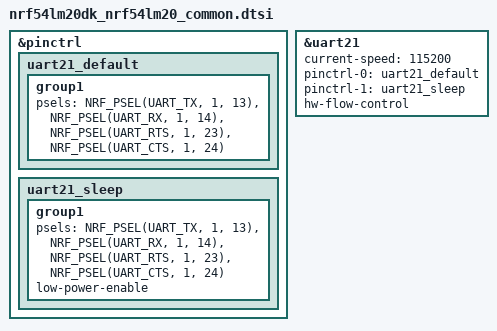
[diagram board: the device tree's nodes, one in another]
/* SPDX-License-Identifier: Apache-2.0 */

/* Test requires loopbacks:
 * P1.13 - P1.14
 * P1.23 - P1.24
 */

&pinctrl {
	uart21_default: uart21_default {
		group1 {
			psels = <NRF_PSEL(UART_TX, 1, 13)>,
				<NRF_PSEL(UART_RX, 1, 14)>,
				<NRF_PSEL(UART_RTS, 1, 23)>,
				<NRF_PSEL(UART_CTS, 1, 24)>;
		};
	};

	uart21_sleep: uart21_sleep {
		group1 {
			psels = <NRF_PSEL(UART_TX, 1, 13)>,
				<NRF_PSEL(UART_RX, 1, 14)>,
				<NRF_PSEL(UART_RTS, 1, 23)>,
				<NRF_PSEL(UART_CTS, 1, 24)>;
			low-power-enable;
		};
	};
};

dut: &uart21 {
	status = "okay";
	current-speed = <115200>;
	pinctrl-0 = <&uart21_default>;
	pinctrl-1 = <&uart21_sleep>;
	pinctrl-names = "default", "sleep";
	hw-flow-control;
};
